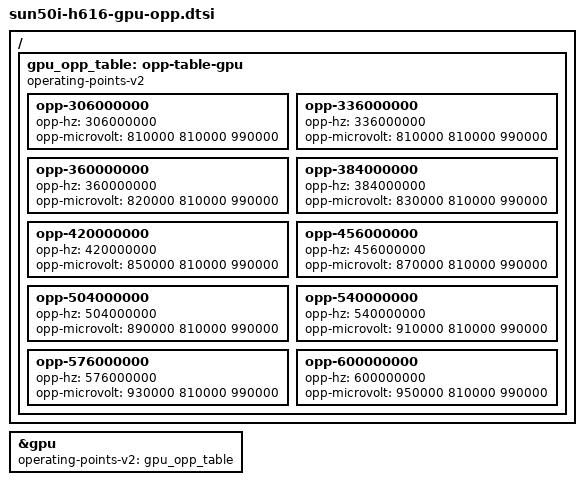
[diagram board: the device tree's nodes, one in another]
// SPDX-License-Identifier: (GPL-2.0+ OR MIT)
/*
 * GPU operating points for Allwinner H616/H618.
 *
 * This file is not in mainline; the values were recovered from the DTB of a
 * KickPi K2B V2 (rev 2.2) image verified to boot on hardware:
 * 306-600 MHz, target 810-950 mV, 990 mV ceiling.
 */
/ {
	gpu_opp_table: opp-table-gpu {
		compatible = "operating-points-v2";

		opp-306000000 {
			opp-hz = /bits/ 64 <306000000>;
			opp-microvolt = <810000 810000 990000>;
		};

		opp-336000000 {
			opp-hz = /bits/ 64 <336000000>;
			opp-microvolt = <810000 810000 990000>;
		};

		opp-360000000 {
			opp-hz = /bits/ 64 <360000000>;
			opp-microvolt = <820000 810000 990000>;
		};

		opp-384000000 {
			opp-hz = /bits/ 64 <384000000>;
			opp-microvolt = <830000 810000 990000>;
		};

		opp-420000000 {
			opp-hz = /bits/ 64 <420000000>;
			opp-microvolt = <850000 810000 990000>;
		};

		opp-456000000 {
			opp-hz = /bits/ 64 <456000000>;
			opp-microvolt = <870000 810000 990000>;
		};

		opp-504000000 {
			opp-hz = /bits/ 64 <504000000>;
			opp-microvolt = <890000 810000 990000>;
		};

		opp-540000000 {
			opp-hz = /bits/ 64 <540000000>;
			opp-microvolt = <910000 810000 990000>;
		};

		opp-576000000 {
			opp-hz = /bits/ 64 <576000000>;
			opp-microvolt = <930000 810000 990000>;
		};

		opp-600000000 {
			opp-hz = /bits/ 64 <600000000>;
			opp-microvolt = <950000 810000 990000>;
		};
	};
};

&gpu {
	operating-points-v2 = <&gpu_opp_table>;
};
